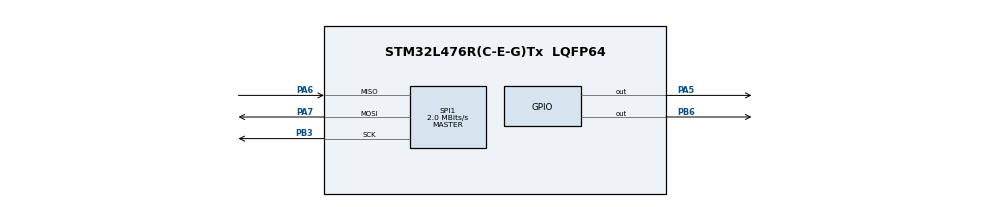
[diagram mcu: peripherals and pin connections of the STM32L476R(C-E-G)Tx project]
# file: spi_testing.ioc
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Mcu.Family=STM32L4
RCC.MSI_VALUE=4000000
PA6.Mode=Full_Duplex_Master
VP_SYS_VS_tim6.Mode=TIM6
FREERTOS.Tasks01=BlinkTask,16,128,Task_Blink,Default,NULL,Dynamic,NULL,NULL;SPI_Manager,24,128,Task_SPI,Default,NULL,Dynamic,NULL,NULL
PA7.Mode=Full_Duplex_Master
SPI1.VirtualType=VM_MASTER
NVIC.TIM6_DAC_IRQn=true\:0\:0\:false\:false\:true\:false\:false\:true
ProjectManager.StackSize=0x400
PB3\ (JTDO-TRACESWO).Signal=SPI1_SCK
VP_FREERTOS_VS_CMSIS_V2.Mode=CMSIS_V2
ProjectManager.TargetToolchain=STM32CubeIDE
SPI1.Direction=SPI_DIRECTION_2LINES
PB6.Signal=GPIO_Output
SPI1.CalculateBaudRate=2.0 MBits/s
RCC.LSE_VALUE=32768
PA5.Signal=GPIO_Output
RCC.HSE_VALUE=8000000
board=custom
RCC.VCOOutputFreq_Value=32000000
SPI1.Mode=SPI_MODE_MASTER
PB3\ (JTDO-TRACESWO).Mode=Full_Duplex_Master
SPI1.DataSize=SPI_DATASIZE_16BIT
Mcu.Name=STM32L476R(C-E-G)Tx
SPI1.NSSPMode=SPI_NSS_PULSE_DISABLE
Mcu.Package=LQFP64
PA6.Signal=SPI1_MISO
NVIC.TimeBase=TIM6_DAC_IRQn
NVIC.TimeBaseIP=TIM6
ProjectManager.HeapSize=0x200
RCC.HSI_VALUE=16000000
NVIC.PriorityGroup=NVIC_PRIORITYGROUP_4
SPI1.BaudRatePrescaler=SPI_BAUDRATEPRESCALER_2
PA7.Signal=SPI1_MOSI

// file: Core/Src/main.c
/* USER CODE BEGIN Header */
/**
  ******************************************************************************
  * @file           : main.c
  * @brief          : Main program body
  ******************************************************************************
  * @attention
  *
  * <h2><center>&copy; Copyright (c) 2021 STMicroelectronics.
  * All rights reserved.</center></h2>
  *
  * This software component is licensed by ST under BSD 3-Clause license,
  * the "License"; You may not use this file except in compliance with the
  * License. You may obtain a copy of the License at:
  *                        opensource.org/licenses/BSD-3-Clause
  *
  ******************************************************************************
  */
/* USER CODE END Header */
#include "main.h"
#include "cmsis_os.h"

/* USER CODE BEGIN Includes */
//#include <stdio.h>
//#include "stm32l4xx_hal_spi.h"
/* USER CODE END Includes */

SPI_HandleTypeDef hspi1;

/* Definitions for BlinkTask */
osThreadId_t BlinkTaskHandle;
const osThreadAttr_t BlinkTask_attributes = {
  .name = "BlinkTask",
  .stack_size = 128 * 4,
  .priority = (osPriority_t) osPriorityBelowNormal,
};
/* Definitions for SPI_Manager */
osThreadId_t SPI_ManagerHandle;
const osThreadAttr_t SPI_Manager_attributes = {
  .name = "SPI_Manager",
  .stack_size = 128 * 4,
  .priority = (osPriority_t) osPriorityNormal,
};

void SystemClock_Config(void);
static void MX_GPIO_Init(void);
static void MX_SPI1_Init(void);
void Task_Blink(void *argument);
void Task_SPI(void *argument);

int main(void)
{

  /* MCU Configuration--------------------------------------------------------*/

  /* Reset of all peripherals, Initializes the Flash interface and the Systick. */
  HAL_Init();

  /* Configure the system clock */
  SystemClock_Config();

  /* Initialize all configured peripherals */
  MX_GPIO_Init();
  MX_SPI1_Init();

  /* Init scheduler */
  osKernelInitialize();

  /* Create the thread(s) */
  /* creation of BlinkTask */
  BlinkTaskHandle = osThreadNew(Task_Blink, NULL, &BlinkTask_attributes);

  /* creation of SPI_Manager */
  SPI_ManagerHandle = osThreadNew(Task_SPI, NULL, &SPI_Manager_attributes);

  /* Start scheduler */
  osKernelStart();

  /* We should never get here as control is now taken by the scheduler */
  /* Infinite loop */
  while (1)
  {

  }
}

void SystemClock_Config(void)
{
  RCC_OscInitTypeDef RCC_OscInitStruct = {0};
  RCC_ClkInitTypeDef RCC_ClkInitStruct = {0};

  /** Initializes the RCC Oscillators according to the specified parameters
  * in the RCC_OscInitTypeDef structure.
  */
  RCC_OscInitStruct.OscillatorType = RCC_OSCILLATORTYPE_MSI;
  RCC_OscInitStruct.MSIState = RCC_MSI_ON;
  RCC_OscInitStruct.MSICalibrationValue = 0;
  RCC_OscInitStruct.MSIClockRange = RCC_MSIRANGE_6;
  RCC_OscInitStruct.PLL.PLLState = RCC_PLL_NONE;
  if (HAL_RCC_OscConfig(&RCC_OscInitStruct) != HAL_OK)
  {
    Error_Handler();
  }
  /** Initializes the CPU, AHB and APB buses clocks
  */
  RCC_ClkInitStruct.ClockType = RCC_CLOCKTYPE_HCLK|RCC_CLOCKTYPE_SYSCLK
                              |RCC_CLOCKTYPE_PCLK1|RCC_CLOCKTYPE_PCLK2;
  RCC_ClkInitStruct.SYSCLKSource = RCC_SYSCLKSOURCE_MSI;
  RCC_ClkInitStruct.AHBCLKDivider = RCC_SYSCLK_DIV1;
  RCC_ClkInitStruct.APB1CLKDivider = RCC_HCLK_DIV1;
  RCC_ClkInitStruct.APB2CLKDivider = RCC_HCLK_DIV1;

  if (HAL_RCC_ClockConfig(&RCC_ClkInitStruct, FLASH_LATENCY_0) != HAL_OK)
  {
    Error_Handler();
  }
  /** Configure the main internal regulator output voltage
  */
  if (HAL_PWREx_ControlVoltageScaling(PWR_REGULATOR_VOLTAGE_SCALE1) != HAL_OK)
  {
    Error_Handler();
  }
}

static void MX_SPI1_Init(void)
{

  /* USER CODE BEGIN SPI1_Init 1 */

  // By default, CS pin should be high (thisis for SPI1).
  HAL_GPIO_WritePin(GPIOB, GPIO_PIN_6, GPIO_PIN_SET);

  /* USER CODE END SPI1_Init 1 */
  /* SPI1 parameter configuration*/
  hspi1.Instance = SPI1;
  hspi1.Init.Mode = SPI_MODE_MASTER;
  hspi1.Init.Direction = SPI_DIRECTION_2LINES;
  hspi1.Init.DataSize = SPI_DATASIZE_16BIT;
  hspi1.Init.CLKPolarity = SPI_POLARITY_LOW;
  hspi1.Init.CLKPhase = SPI_PHASE_1EDGE;
  hspi1.Init.NSS = SPI_NSS_SOFT;
  hspi1.Init.BaudRatePrescaler = SPI_BAUDRATEPRESCALER_2;
  hspi1.Init.FirstBit = SPI_FIRSTBIT_MSB;
  hspi1.Init.TIMode = SPI_TIMODE_DISABLE;
  hspi1.Init.CRCCalculation = SPI_CRCCALCULATION_DISABLE;
  hspi1.Init.CRCPolynomial = 7;
  hspi1.Init.CRCLength = SPI_CRC_LENGTH_DATASIZE;
  hspi1.Init.NSSPMode = SPI_NSS_PULSE_DISABLE;
  if (HAL_SPI_Init(&hspi1) != HAL_OK)
  {
    Error_Handler();
  }

}

static void MX_GPIO_Init(void)
{
  GPIO_InitTypeDef GPIO_InitStruct = {0};

  /* GPIO Ports Clock Enable */
  __HAL_RCC_GPIOA_CLK_ENABLE();
  __HAL_RCC_GPIOB_CLK_ENABLE();

  /*Configure GPIO pin Output Level */
  HAL_GPIO_WritePin(GPIOA, GPIO_PIN_5, GPIO_PIN_RESET);

  /*Configure GPIO pin Output Level */
  HAL_GPIO_WritePin(GPIOB, GPIO_PIN_6, GPIO_PIN_RESET);

  /*Configure GPIO pin : PA5 */
  GPIO_InitStruct.Pin = GPIO_PIN_5;
  GPIO_InitStruct.Mode = GPIO_MODE_OUTPUT_PP;
  GPIO_InitStruct.Pull = GPIO_NOPULL;
  GPIO_InitStruct.Speed = GPIO_SPEED_FREQ_LOW;
  HAL_GPIO_Init(GPIOA, &GPIO_InitStruct);

  /*Configure GPIO pin : PB6 */
  GPIO_InitStruct.Pin = GPIO_PIN_6;
  GPIO_InitStruct.Mode = GPIO_MODE_OUTPUT_PP;
  GPIO_InitStruct.Pull = GPIO_NOPULL;
  GPIO_InitStruct.Speed = GPIO_SPEED_FREQ_LOW;
  HAL_GPIO_Init(GPIOB, &GPIO_InitStruct);

}

void Task_Blink(void *argument)
{
  /* USER CODE BEGIN 5 */
  /* Infinite loop */
  for(;;)
  {
	  HAL_GPIO_TogglePin(GPIOA, GPIO_PIN_5);
	  osDelay(1000);
  }
  /* USER CODE END 5 */
}

void Task_SPI(void *argument)
{
  /* USER CODE BEGIN Task_SPI */
	uint8_t txData[4] = { 1, 2, 5, 3 };

  /* Infinite loop */
  for(;;)
  {
  	// Send message over SPI1
  	HAL_GPIO_WritePin(GPIOB, GPIO_PIN_6, GPIO_PIN_RESET);
  	HAL_SPI_Transmit(&hspi1, txData, 4, HAL_MAX_DELAY);
  	HAL_GPIO_WritePin(GPIOB, GPIO_PIN_6, GPIO_PIN_SET);
	  osDelay(10);
  }
  /* USER CODE END Task_SPI */
}

 /**
  * @brief  Period elapsed callback in non blocking mode
  * @note   This function is called  when TIM6 interrupt took place, inside
  * HAL_TIM_IRQHandler(). It makes a direct call to HAL_IncTick() to increment
  * a global variable "uwTick" used as application time base.
  * @param  htim : TIM handle
  * @retval None
  */
void HAL_TIM_PeriodElapsedCallback(TIM_HandleTypeDef *htim)
{
  if (htim->Instance == TIM6) {
    HAL_IncTick();
  }
}

void Error_Handler(void)
{
  __disable_irq();
  while (1)
  {
  }
}

/************************ (C) COPYRIGHT STMicroelectronics *****END OF FILE****/
